# PIC16LF1707 register map
Vendor: Microchip
Architecture 16Exxx. Special function registers and configuration words.
Registers are 8-bit, read-write, reset 0x0 unless marked. A register's access mark holds for its fields unless they carry their own. Addresses are absolute, and some are shared; only a register's first bit layout is shown; lines under a group give offsets from that group; [hi:lo] are bit positions; {n}, {i} and the like mark numbered series; 'fields as' and 'values as' point back to an identical list; <NAME> marks a mode.

## Further device data
pins=1: Vdd; 2: RA5/SOSCI/CLKIN/OSC1; 3: RA4/AN3/SOSCO/CLKOUT/OSC2; 4: RA3/MCLR/Vpp; 5: RC5; 6: RC4; 7: RC3/AN7/OPA2OUT; 8: RC6/AN9/OPA2IN-; 9: RC7/AN9/OPA2IN+; 10: RB7; 11: RB6; 12: RB5/AN11/OPA1IN+; 13: RB4/AN10/OPA1IN+; 14: RC2/AN6/OPA1OUT; 15: RC1/AN5; 16: RC0/AN4; 17: RA2/AN2/ZCD; 18: RA1/AN1/Vref+/ICSPCLK; 19: RA0/AN0/Vref-/ICSPDAT; 20: Vss

## tmr
0x1A TMR2 — 8-bit period timer
0x1B PR2 reset 0xFF
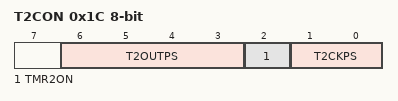
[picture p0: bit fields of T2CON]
0x1C T2CON
  [6:3] T2OUTPS, [2] TMR2ON, [1:0] T2CKPS

## cmp_zxover_ctrl
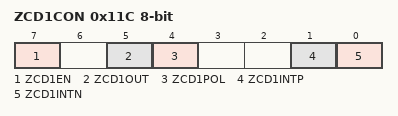
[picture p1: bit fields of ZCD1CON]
0x11C ZCD1CON reset not defined — (power-on value 0-x0--00)
  [7] ZCD1EN, [5] ZCD1OUT ro, [4] ZCD1POL, [1] ZCD1INTP, [0] ZCD1INTN

## mssp
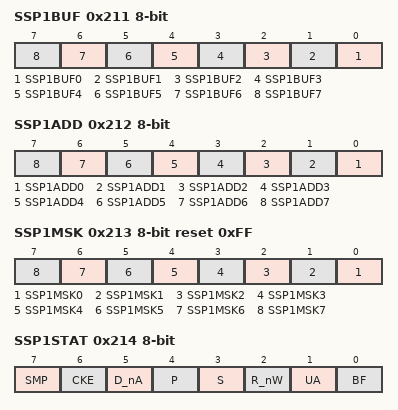
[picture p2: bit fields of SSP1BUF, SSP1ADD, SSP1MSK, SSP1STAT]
0x211 SSP1BUF reset not defined — (power-on value xxxxxxxx)
  [n] SSP1BUF{n} (n=0..7)
0x212 SSP1ADD
  [n] SSP1ADD{n} (n=0..7)
0x213 SSP1MSK reset 0xFF
  [n] SSP1MSK{n} (n=0..7)
0x214 SSP1STAT
  [7] SMP, [6] CKE, [5] D_nA ro, [4] P ro, [3] S ro, [2] R_nW ro, [1] UA ro, [0] BF ro
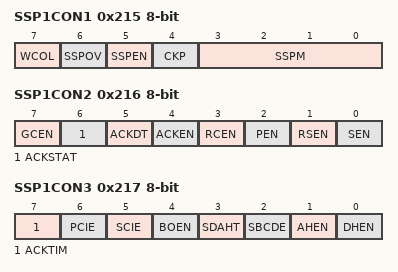
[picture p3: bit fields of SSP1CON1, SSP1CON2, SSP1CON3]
0x215 SSP1CON1
  [7] WCOL ro, [6] SSPOV ro, [5] SSPEN, [4] CKP, [3:0] SSPM
0x216 SSP1CON2
  [7] GCEN, [6] ACKSTAT ro, [5] ACKDT, [4] ACKEN, [3] RCEN, [2] PEN, [1] RSEN, [0] SEN
0x217 SSP1CON3
  [7] ACKTIM ro, [6] PCIE, [5] SCIE, [4] BOEN, [3] SDAHT, [2] SBCDE, [1] AHEN, [0] DHEN

## ccp
0x291 CCPR1L reset not defined — (power-on value xxxxxxxx)
0x292 CCPR1H reset not defined — (power-on value xxxxxxxx)
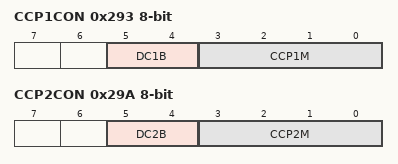
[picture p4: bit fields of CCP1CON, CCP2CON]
0x293 CCP1CON
  [5:4] DC1B, [3:0] CCP1M
0x298 CCPR2L reset not defined — (power-on value xxxxxxxx)
0x299 CCPR2H reset not defined — (power-on value xxxxxxxx)
0x29A CCP2CON
  [5:4] DC2B, [3:0] CCP2M

## amp_opamp_hvpump
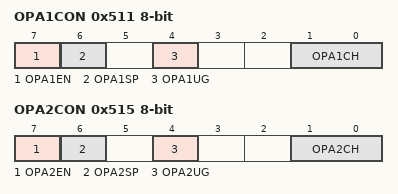
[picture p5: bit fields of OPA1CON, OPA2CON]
0x511 OPA1CON
  [7] OPA1EN, [6] OPA1SP, [4] OPA1UG, [1:0] OPA1CH
0x515 OPA2CON
  [7] OPA2EN, [6] OPA2SP, [4] OPA2UG, [1:0] OPA2CH

## CONFIG — Configuration words, addresses in ProgramSpace
0x8007 CONFIG1 14-bit reset 0x3FFF
  [11] CLKOUTEN — Clock Out Enable
    1=OFF (CLKOUT function is disabled. I/O or oscillator function on the CLKOUT pin); 0=ON (CLKOUT function is enabled on the CLKOUT pin)
  [10:9] BOREN — Brown-out Reset Enable
    3=ON (Brown-out Reset enabled); 2=NSLEEP (Brown-out Reset enabled while running and disabled in Sleep); 1=SBODEN (Brown-out Reset controlled by the SBOREN bit in the BORCON register); 0=OFF (Brown-out Reset disabled)
  [7] CP — Flash Program Memory Code Protection
    1=OFF (Program memory code protection is disabled); 0=ON (Program memory code protection is enabled)
  [6] MCLRE — MCLR Pin Function Select
    1=ON (MCLR/VPP pin function is MCLR); 0=OFF (MCLR/VPP pin function is digital input)
  [5] PWRTE — Power-up Timer Enable
    1=OFF (PWRT disabled); 0=ON (PWRT enabled)
  [4:3] WDTE — Watchdog Timer Enable
    3=ON (WDT enabled); 2=NSLEEP (WDT enabled while running and disabled in Sleep); 1=SWDTEN (WDT controlled by the SWDTEN bit in the WDTCON register); 0=OFF (WDT disabled)
  [1:0] FOSC — Oscillator Selection Bits
    3=ECH (External oscillator, high power. I/O function on RA4); 2=ECM (External oscillator, medium power. I/O function on RA4); 1=ECL (External oscillator, low power. I/O function on RA4); 0=INTOSC (Internal HFINTOSC. I/O function on RA4 and RA5.)
0x8008 CONFIG2 14-bit reset 0x3FFF
  [13] LVP — Low-Voltage Programming Enable
    1=ON (Low-voltage programming enabled); 0=OFF (High-voltage on MCLR/VPP must be used for programming)
  [12] DEBUG — In-Circuit Debugger Mode
    1=OFF (In-Circuit Debugger disabled, ICSPCLK and ICSPDAT are general purpose I/O pins); 0=ON (In-Circuit Debugger enabled, ICSPCLK and ICSPDAT are dedicated to the debugger)
  [11] LPBOR — Low-Power Brown Out Reset
    1=OFF (Low-Power BOR is disabled); 0=ON (Low-Power BOR is enabled)
  [10] BORV — Brown-out Reset Voltage Selection
    1=LO (Brown-out Reset Voltage (Vbor), low trip point selected.); 0=HI (Brown-out Reset Voltage (Vbor), high trip point selected.)
  [9] STVREN — Stack Overflow/Underflow Reset Enable
    1=ON (Stack Overflow or Underflow will cause a Reset); 0=OFF (Stack Overflow or Underflow will not cause a Reset)
  [8] PLLEN — Phase Lock Loop enable
    1=ON (4x PLL is enabled); 0=OFF (4x PLL is disabled)
  [7] ZCDDIS — Zero-cross detect disable
    1=ON (ZCD disabled. ZCD can be enabled by setting the ZCDSEN bit of ZCDCON); 0=OFF (ZCD always enabled)
  [2] PPS1WAY — Peripheral Pin Select one-way control
    1=ON (The PPSLOCK bit cannot be cleared once it is set by software); 0=OFF (The PPSLOCK bit can be set and cleared repeatedly by software)
  [1:0] WRT — Flash Memory Self-Write Protection
    3=OFF (Write protection off); 2=BOOT (000h to 1FFh write protected, 200h to 1FFFh may be modified by EECON control); 1=HALF (000h to FFFh write protected, 1000h to 1FFFh may be modified by EECON control); 0=ALL (000h to 1FFFh write protected, no addresses may be modified by EECON control)
